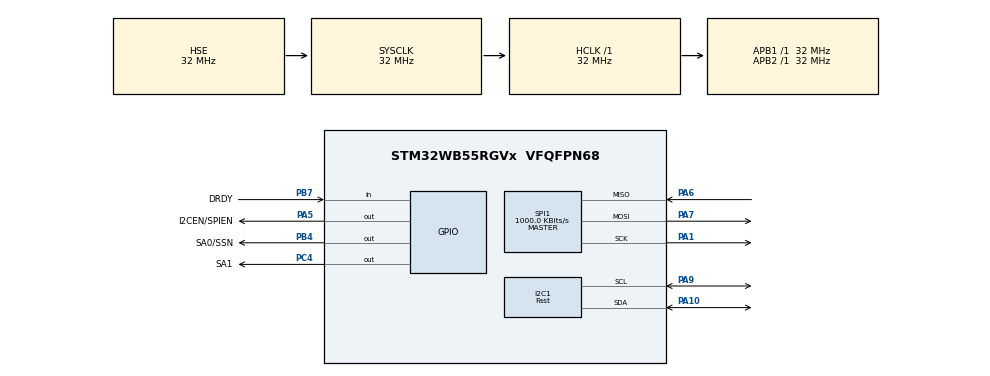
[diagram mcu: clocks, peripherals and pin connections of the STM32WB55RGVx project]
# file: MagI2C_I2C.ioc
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I2C1.CustomTiming=Disabled
I2C1.I2C_Speed_Mode=I2C_Fast
I2C1.Timing=0x00300F38
Mcu.Family=STM32WB
Mcu.Name=STM32WB55RGVx
Mcu.Package=VFQFPN68
NVIC.PriorityGroup=NVIC_PRIORITYGROUP_4
OSC_IN.Mode=HSE-External-Oscillator
OSC_IN.Signal=RCC_OSC_IN
OSC_OUT.Mode=HSE-External-Oscillator
OSC_OUT.Signal=RCC_OSC_OUT
PA1.Mode=Full_Duplex_Master
PA1.Signal=SPI1_SCK
PA10.Mode=I2C
PA10.Signal=I2C1_SDA
PA13.GPIO_Label=JTMS
PA13.Mode=Serial_Wire
PA13.Signal=SYS_JTMS-SWDIO
PA14.GPIO_Label=JTCK
PA14.Mode=Serial_Wire
PA14.Signal=SYS_JTCK-SWCLK
PA5.GPIO_Label=I2CEN/SPIEN
PA5.GPIO_PuPd=GPIO_PULLUP
PA5.Signal=GPIO_Output
PA6.Mode=Full_Duplex_Master
PA6.Signal=SPI1_MISO
PA7.Mode=Full_Duplex_Master
PA7.Signal=SPI1_MOSI
PA9.Mode=I2C
PA9.Signal=I2C1_SCL
PB3.GPIO_Label=JTDO
PB3.Signal=SYS_JTDO-SWO
PB4.GPIO_Label=SA0/SSN
PB4.GPIO_PuPd=GPIO_PULLUP
PB4.Signal=GPIO_Output
PB7.GPIO_Label=DRDY
PB7.Signal=GPIO_Input
PC13.Mode=SYS_WakeUp1
PC13.Signal=SYS_WKUP2
PC4.GPIO_Label=SA1
PC4.GPIO_PuPd=GPIO_PULLUP
PC4.Signal=GPIO_Output
ProjectManager.HeapSize=0x200
ProjectManager.StackSize=0x400
ProjectManager.TargetToolchain=STM32CubeIDE
RCC.ADCFreq_Value=48000000
RCC.AHBFreq_Value=32000000
RCC.APB1Freq_Value=32000000
RCC.APB1TimFreq_Value=32000000
RCC.APB2Freq_Value=32000000
RCC.APB2TimFreq_Value=32000000
RCC.APB3Freq_Value=16000000
RCC.CortexFreq_Value=32000000
RCC.HCLKFreq_Value=32000000
RCC.HSE_VALUE=32000000
RCC.HSI48_VALUE=48000000
RCC.HSI_VALUE=16000000
RCC.LSE_VALUE=32768
RCC.PLLN=32
RCC.PLLSAI1N=24
RCC.SMPSCLockSelectionVirtual=RCC_SMPSCLKSOURCE_HSI
RCC.SMPSCLockSelectionVirtualVirtual=RCC_SMPSCLKSOURCE_HSI
RCC.SMPSDivider=1
RCC.SYSCLKFreq_VALUE=32000000
RCC.SYSCLKSource=RCC_SYSCLKSOURCE_HSE
RCC.USBFreq_Value=48000000
RCC.VCOOutputFreq_Value=128000000
SPI1.BaudRatePrescaler=SPI_BAUDRATEPRESCALER_32
SPI1.CLKPolarity=SPI_POLARITY_LOW
SPI1.CalculateBaudRate=1000.0 KBits/s
SPI1.DataSize=SPI_DATASIZE_8BIT
SPI1.Direction=SPI_DIRECTION_2LINES
SPI1.Mode=SPI_MODE_MASTER
SPI1.VirtualType=VM_MASTER
board=NUCLEO-WB55RG

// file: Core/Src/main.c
/* USER CODE BEGIN Header */
/**
  ******************************************************************************
  * @file           : main.c
  * @brief          : Main program body
  ******************************************************************************
  * @attention
  *
  * Copyright (c) 2023 STMicroelectronics.
  * All rights reserved.
  *
  * This software is licensed under terms that can be found in the LICENSE file
  * in the root directory of this software component.
  * If no LICENSE file comes with this software, it is provided AS-IS.
  *
  ******************************************************************************
  */
/* USER CODE END Header */
#include "main.h"
#include "i2c.h"
#include "spi.h"
#include "gpio.h"

/* USER CODE BEGIN Includes */
#include "MagI2C_driver.h"
/* USER CODE END Includes */

/* USER CODE BEGIN PV */
mag_field get_meas = {0};
/* USER CODE END PV */

void SystemClock_Config(void);
void PeriphCommonClock_Config(void);

int main(void)
{

  /* MCU Configuration--------------------------------------------------------*/

  /* Reset of all peripherals, Initializes the Flash interface and the Systick. */
  HAL_Init();

  /* Configure the system clock */
  SystemClock_Config();

/* Configure the peripherals common clocks */
  PeriphCommonClock_Config();

  /* Initialize all configured peripherals */
  MX_GPIO_Init();
  MX_I2C1_Init();
  MX_SPI1_Init();
  /* USER CODE BEGIN 2 */
  MagI2C_config_I2C(&hi2c1);
  /* USER CODE END 2 */

  /* Infinite loop */
  /* USER CODE BEGIN WHILE */
  while (1)
  {
	 get_meas = MagI2C_get_meas_I2C();
	 HAL_Delay(100);
    /* USER CODE END WHILE */

  }
}

void SystemClock_Config(void)
{
  RCC_OscInitTypeDef RCC_OscInitStruct = {0};
  RCC_ClkInitTypeDef RCC_ClkInitStruct = {0};

  /** Configure the main internal regulator output voltage
  */
  __HAL_PWR_VOLTAGESCALING_CONFIG(PWR_REGULATOR_VOLTAGE_SCALE1);

  /** Initializes the RCC Oscillators according to the specified parameters
  * in the RCC_OscInitTypeDef structure.
  */
  RCC_OscInitStruct.OscillatorType = RCC_OSCILLATORTYPE_HSI|RCC_OSCILLATORTYPE_HSE;
  RCC_OscInitStruct.HSEState = RCC_HSE_ON;
  RCC_OscInitStruct.HSIState = RCC_HSI_ON;
  RCC_OscInitStruct.HSICalibrationValue = RCC_HSICALIBRATION_DEFAULT;
  RCC_OscInitStruct.PLL.PLLState = RCC_PLL_NONE;
  if (HAL_RCC_OscConfig(&RCC_OscInitStruct) != HAL_OK)
  {
    Error_Handler();
  }

  /** Configure the SYSCLKSource, HCLK, PCLK1 and PCLK2 clocks dividers
  */
  RCC_ClkInitStruct.ClockType = RCC_CLOCKTYPE_HCLK4|RCC_CLOCKTYPE_HCLK2
                              |RCC_CLOCKTYPE_HCLK|RCC_CLOCKTYPE_SYSCLK
                              |RCC_CLOCKTYPE_PCLK1|RCC_CLOCKTYPE_PCLK2;
  RCC_ClkInitStruct.SYSCLKSource = RCC_SYSCLKSOURCE_HSE;
  RCC_ClkInitStruct.AHBCLKDivider = RCC_SYSCLK_DIV1;
  RCC_ClkInitStruct.APB1CLKDivider = RCC_HCLK_DIV1;
  RCC_ClkInitStruct.APB2CLKDivider = RCC_HCLK_DIV1;
  RCC_ClkInitStruct.AHBCLK2Divider = RCC_SYSCLK_DIV1;
  RCC_ClkInitStruct.AHBCLK4Divider = RCC_SYSCLK_DIV1;

  if (HAL_RCC_ClockConfig(&RCC_ClkInitStruct, FLASH_LATENCY_1) != HAL_OK)
  {
    Error_Handler();
  }
}

void PeriphCommonClock_Config(void)
{
  RCC_PeriphCLKInitTypeDef PeriphClkInitStruct = {0};

  /** Initializes the peripherals clock
  */
  PeriphClkInitStruct.PeriphClockSelection = RCC_PERIPHCLK_SMPS;
  PeriphClkInitStruct.SmpsClockSelection = RCC_SMPSCLKSOURCE_HSI;
  PeriphClkInitStruct.SmpsDivSelection = RCC_SMPSCLKDIV_RANGE0;

  if (HAL_RCCEx_PeriphCLKConfig(&PeriphClkInitStruct) != HAL_OK)
  {
    Error_Handler();
  }
}

void Error_Handler(void)
{
  __disable_irq();
  while (1)
  {
  }
}
